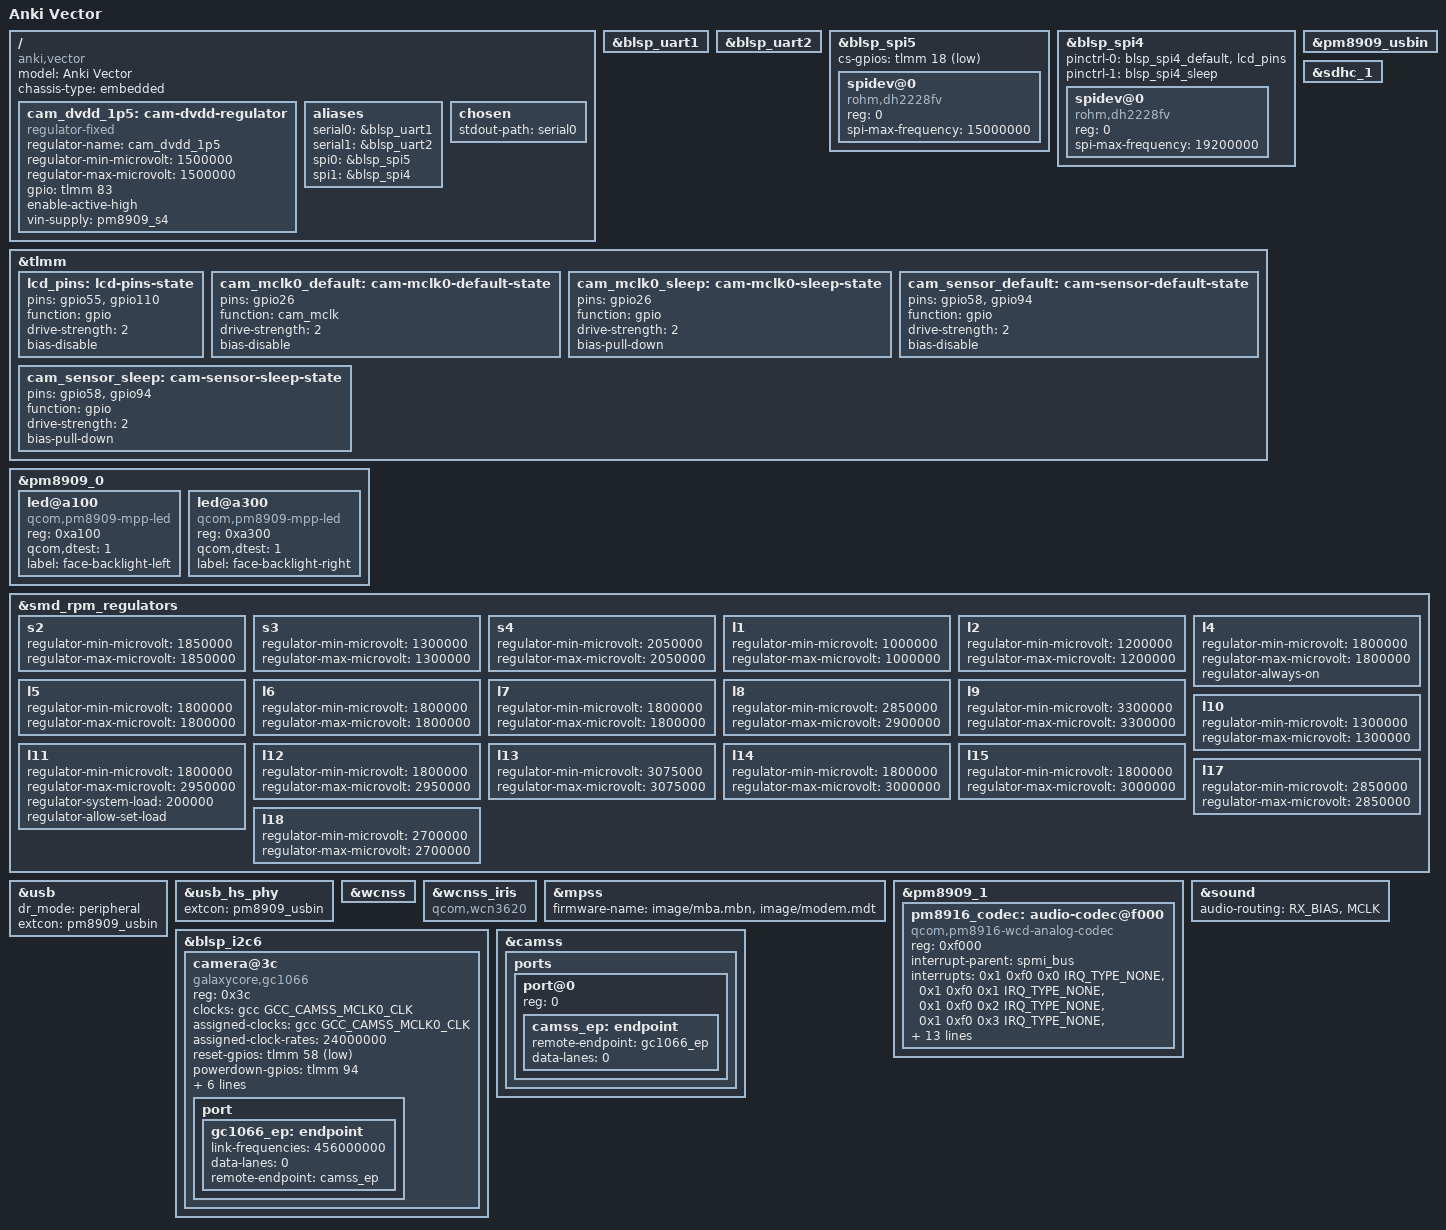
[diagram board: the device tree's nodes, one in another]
// SPDX-License-Identifier: GPL-2.0-only

/dts-v1/;

#include "qcom-msm8909-pm8909.dtsi"
#include "qcom-apq8009-modem-qdsp6.dtsi"

#include <dt-bindings/clock/qcom,gcc-msm8909.h>
#include <dt-bindings/gpio/gpio.h>
#include <dt-bindings/input/input.h>
#include <dt-bindings/interrupt-controller/irq.h>
#include <dt-bindings/leds/common.h>
#include <dt-bindings/pinctrl/qcom,pmic-mpp.h>

/ {
	model = "Anki Vector";
	compatible = "anki,vector", "qcom,msm8909";
	chassis-type = "embedded";

	// there's an external regulator for the camera
	// i can't say i understand why
	// S4 is 2.05V, VOUT (cam VDD) is 1.50V
	// GPIO 83 -> EN
	cam_dvdd_1p5: cam-dvdd-regulator {
		compatible = "regulator-fixed";
		regulator-name = "cam_dvdd_1p5";
		regulator-min-microvolt = <1500000>;
		regulator-max-microvolt = <1500000>;
		gpio = <&tlmm 83 GPIO_ACTIVE_HIGH>;
		enable-active-high;
		vin-supply = <&pm8909_s4>;
	};

	aliases {
		serial0 = &blsp_uart1; // kernel logs and shell
		serial1 = &blsp_uart2; // body
		spi0 = &blsp_spi5; // imu
		spi1 = &blsp_spi4; // lcd
	};

	chosen {
		#address-cells = <1>;
		#size-cells = <1>;
		ranges;

		stdout-path = "serial0";
	};
};

&blsp_uart1 {
	status = "okay";
};

&blsp_uart2 {
	status = "okay";
};

// imu
&blsp_spi5 {
	status = "okay";
	cs-gpios = <&tlmm 18 GPIO_ACTIVE_LOW>;

	spidev@0 {
        // the linux people don't like spidev
        // but Vector's software wants it.
        // only a few devices have exceptions.
        // this device is one of them
		compatible = "rohm,dh2228fv";
		reg = <0>;
		spi-max-frequency = <15000000>;
	};
};

// lcd
&blsp_spi4 {
	status = "okay";
	pinctrl-0 = <&blsp_spi4_default &lcd_pins>;
	pinctrl-1 = <&blsp_spi4_sleep>;

	spidev@0 {
		compatible = "rohm,dh2228fv";
		reg = <0>;
		spi-max-frequency = <19200000>;
	};
};

// display reset and wrx
&tlmm {
	lcd_pins: lcd-pins-state {
		pins = "gpio55", "gpio110";
		function = "gpio";
		drive-strength = <2>;
		bias-disable;
	};

	cam_mclk0_default: cam-mclk0-default-state {
		pins = "gpio26";
		function = "cam_mclk";
		drive-strength = <2>;
		bias-disable;
	};

	cam_mclk0_sleep: cam-mclk0-sleep-state {
		pins = "gpio26";
		function = "gpio";
		drive-strength = <2>;
		bias-pull-down;
	};

	cam_sensor_default: cam-sensor-default-state {
		pins = "gpio58", "gpio94";
		function = "gpio";
		drive-strength = <2>;
		bias-disable;
	};

	cam_sensor_sleep: cam-sensor-sleep-state {
		pins = "gpio58", "gpio94";
		function = "gpio";
		drive-strength = <2>;
		bias-pull-down;
	};
};

&pm8909_0 {
	led@a100 {
		compatible = "qcom,pm8909-mpp-led";
		reg = <0xa100>;
		qcom,dtest = <1>;
		label = "face-backlight-left";
	};

	led@a300 {
		compatible = "qcom,pm8909-mpp-led";
		reg = <0xa300>;
		qcom,dtest = <1>;
		label = "face-backlight-right";
	};
};

&pm8909_usbin {
	status = "okay";
};

&sdhc_1 {
	status = "okay";
};

&smd_rpm_regulators {
	s2 {
		regulator-min-microvolt = <1850000>;
		regulator-max-microvolt = <1850000>;
	};

	s3 {
		regulator-min-microvolt = <1300000>;
		regulator-max-microvolt = <1300000>;
	};

	s4 {
		regulator-min-microvolt = <2050000>;
		regulator-max-microvolt = <2050000>;
	};

	l1 {
		regulator-min-microvolt = <1000000>;
		regulator-max-microvolt = <1000000>;
	};

	l2 {
		regulator-min-microvolt = <1200000>;
		regulator-max-microvolt = <1200000>;
	};

	l4 {
		regulator-min-microvolt = <1800000>;
		regulator-max-microvolt = <1800000>;
		regulator-always-on;
	};

	l5 {
		regulator-min-microvolt = <1800000>;
		regulator-max-microvolt = <1800000>;
	};

	l6 {
		regulator-min-microvolt = <1800000>;
		regulator-max-microvolt = <1800000>;
	};

	l7 {
		regulator-min-microvolt = <1800000>;
		regulator-max-microvolt = <1800000>;
	};

	l8 {
		regulator-min-microvolt = <2850000>;
		regulator-max-microvolt = <2900000>;
	};

	l9 {
		regulator-min-microvolt = <3300000>;
		regulator-max-microvolt = <3300000>;
	};

	l10 {
		regulator-min-microvolt = <1300000>;
		regulator-max-microvolt = <1300000>;
	};

	l11 {
		regulator-min-microvolt = <1800000>;
		regulator-max-microvolt = <2950000>;
		regulator-system-load = <200000>;
		regulator-allow-set-load;
	};

	l12 {
		regulator-min-microvolt = <1800000>;
		regulator-max-microvolt = <2950000>;
	};

	l13 {
		regulator-min-microvolt = <3075000>;
		regulator-max-microvolt = <3075000>;
	};

	l14 {
		regulator-min-microvolt = <1800000>;
		regulator-max-microvolt = <3000000>;
	};

	l15 {
		regulator-min-microvolt = <1800000>;
		regulator-max-microvolt = <3000000>;
	};

	l17 {
		regulator-min-microvolt = <2850000>;
		regulator-max-microvolt = <2850000>;
	};

	l18 {
		regulator-min-microvolt = <2700000>;
		regulator-max-microvolt = <2700000>;
	};
};

&usb {
	dr_mode = "peripheral";
	extcon = <&pm8909_usbin>;
	status = "okay";
};

&usb_hs_phy {
	extcon = <&pm8909_usbin>;
	status = "okay";
};

&wcnss {
	status = "okay";
};

&wcnss_iris {
	compatible = "qcom,wcn3620";
};

&mpss {
	firmware-name = "image/mba.mbn", "image/modem.mdt";
};

&pm8909_1 {
	pm8916_codec: audio-codec@f000 {
		compatible = "qcom,pm8916-wcd-analog-codec";
		reg = <0xf000>;
		interrupt-parent = <&spmi_bus>;
		interrupts = <0x1 0xf0 0x0 IRQ_TYPE_NONE>,
			     <0x1 0xf0 0x1 IRQ_TYPE_NONE>,
			     <0x1 0xf0 0x2 IRQ_TYPE_NONE>,
			     <0x1 0xf0 0x3 IRQ_TYPE_NONE>,
			     <0x1 0xf0 0x4 IRQ_TYPE_NONE>,
			     <0x1 0xf0 0x5 IRQ_TYPE_NONE>,
			     <0x1 0xf0 0x6 IRQ_TYPE_NONE>,
			     <0x1 0xf0 0x7 IRQ_TYPE_NONE>,
			     <0x1 0xf1 0x0 IRQ_TYPE_NONE>,
			     <0x1 0xf1 0x1 IRQ_TYPE_NONE>,
			     <0x1 0xf1 0x2 IRQ_TYPE_NONE>,
			     <0x1 0xf1 0x3 IRQ_TYPE_NONE>,
			     <0x1 0xf1 0x4 IRQ_TYPE_NONE>,
			     <0x1 0xf1 0x5 IRQ_TYPE_NONE>;
		interrupt-names = "cdc_spk_cnp_int",
				  "cdc_spk_clip_int",
				  "cdc_spk_ocp_int",
				  "mbhc_ins_rem_det1",
				  "mbhc_but_rel_det",
				  "mbhc_but_press_det",
				  "mbhc_ins_rem_det",
				  "mbhc_switch_int",
				  "cdc_ear_ocp_int",
				  "cdc_hphr_ocp_int",
				  "cdc_hphl_ocp_det",
				  "cdc_ear_cnp_int",
				  "cdc_hphr_cnp_int",
				  "cdc_hphl_cnp_int";
		vdd-cdc-io-supply = <&pm8909_l5>;
		vdd-cdc-tx-rx-cx-supply = <&pm8909_l5>;
		vdd-micbias-supply = <&pm8909_l13>;
		#sound-dai-cells = <1>;
	};
};

&sound {
	audio-routing =
		"RX_BIAS", "MCLK";
};

// camera
&blsp_i2c6 {
	status = "okay";

	camera@3c {
		compatible = "galaxycore,gc1066";
		reg = <0x3c>;

		clocks = <&gcc GCC_CAMSS_MCLK0_CLK>;
		clock-names = "xvclk";

		assigned-clocks = <&gcc GCC_CAMSS_MCLK0_CLK>;
		assigned-clock-rates = <24000000>;

		reset-gpios = <&tlmm 58 GPIO_ACTIVE_LOW>;
		powerdown-gpios = <&tlmm 94 GPIO_ACTIVE_HIGH>;

		avdd-supply = <&pm8909_l17>;
		vddio-supply = <&pm8909_l4>;
		dvdd-supply = <&cam_dvdd_1p5>;

		pinctrl-names = "default", "sleep";
		pinctrl-0 = <&cam_mclk0_default &cam_sensor_default>;
		pinctrl-1 = <&cam_mclk0_sleep &cam_sensor_sleep>;

		port {
			gc1066_ep: endpoint {
				link-frequencies = /bits/ 64 <456000000>;
				data-lanes = <0>;
				remote-endpoint = <&camss_ep>;
			};
		};
	};
};

&camss {
	status = "okay";

	ports {
		port@0 {
			reg = <0>;
			camss_ep: endpoint {
				remote-endpoint = <&gc1066_ep>;
				data-lanes = <0>;
			};
		};
	};
};
